# GD32E502 register map
File version: 1.0
CPU: CM33 r0p4, little endian, MPU, FPU, 4 interrupt priority bits
Registers are 32-bit, read-write, reset 0x0 unless marked. A register's access mark holds for its fields unless they carry their own. Offsets are from the block's base; [hi:lo] are bit positions; {n}, {i} and the like mark numbered series.

## TIMER0 — Advanced-timers
Base 0x40012C00
Same registers: TIMER7 0x40013400, TIMER19 0x40015000, TIMER20 0x40015400
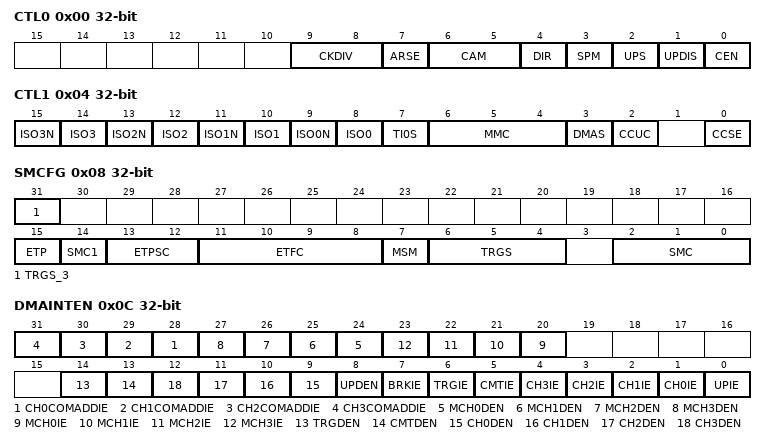
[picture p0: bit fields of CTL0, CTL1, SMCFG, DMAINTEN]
0x00 CTL0 — control register 0
  [9:8] CKDIV — Clock division
  [7] ARSE — Auto-reload shadow enable
  [6:5] CAM — Counter aligns mode selection
  [4] DIR — Direction
  [3] SPM — Single pulse mode
  [2] UPS — Update source
  [1] UPDIS — Update disable
  [0] CEN — Counter enable
0x04 CTL1 — control register 1
  [2n+9] ISO{n}N (n=0..3) — Idle state of channel {n} complementary output
  [2n+8] ISO{n} (n=0..3) — Idle state of channel {n} output
  [7] TI0S — Channel 0 trigger input selection
  [6:4] MMC — Master mode control
  [3] DMAS — DMA request source selection
  [2] CCUC — Commutation control shadow register update control
  [0] CCSE — Commutation control shadow enable
0x08 SMCFG — slave mode configuration register
  [31] TRGS_3 — 3th bit of TRGS
  [15] ETP — External trigger polarity
  [14] SMC1 — Part of SMC for enable External clock mode1
  [13:12] ETPSC — External trigger prescaler
  [11:8] ETFC — External trigger filter control
  [7] MSM — Master/Slave mode
  [6:4] TRGS — Trigger selection
  [2:0] SMC — Slave mode selection
0x0C DMAINTEN — DMA/Interrupt enable register
  [n+28] CH{n}COMADDIE (n=0..3) — Channel {n} additional compare interrupt enable
  [n+24] MCH{n}DEN (n=0..3) — Multi mode channel {n} capture/compare DMA request enable
  [n+20] MCH{n}IE (n=0..3) — Multi mode channel {n} capture/compare interrupt enable
  [14] TRGDEN — Trigger DMA request enable
  [13] CMTDEN — Commutation DMA request enable
  [n+9] CH{n}DEN (n=0..3) — Channel {n} capture/compare DMA request enable
  [8] UPDEN — Update DMA request enable
  [7] BRKIE — Break interrupt enable
  [6] TRGIE — Trigger interrupt enable
  [5] CMTIE — commutation interrupt enable
  [n+1] CH{n}IE (n=0..3) — Channel {n} capture/compare interrupt enable
  [0] UPIE — Update interrupt enable
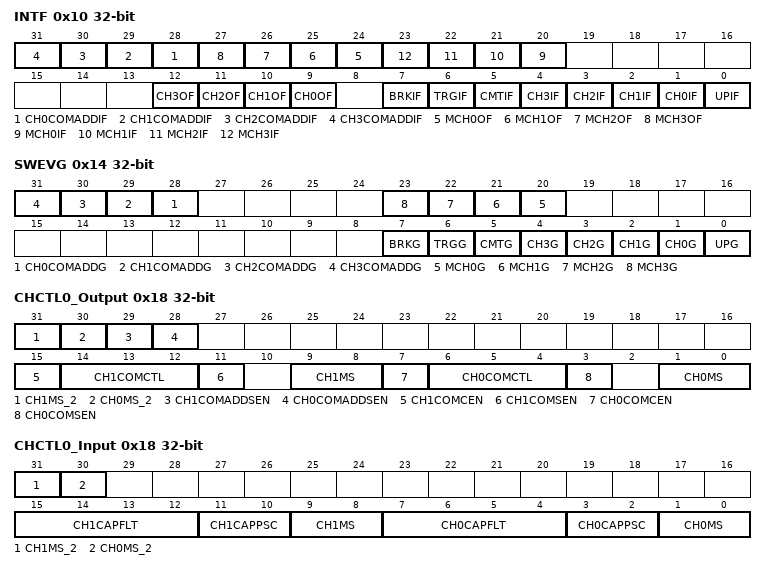
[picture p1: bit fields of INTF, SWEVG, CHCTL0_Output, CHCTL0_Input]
0x10 INTF — Interrupt flag register
  [n+28] CH{n}COMADDIF (n=0..3) — Channel {n} additional compare interrupt flag
  [n+24] MCH{n}OF (n=0..3) — Multi mode channel {n} over capture flag
  [n+20] MCH{n}IF (n=0..3) — Multi mode channel {n} capture/compare interrupt flag
  [n+9] CH{n}OF (n=0..3) — Channel {n} over capture flag
  [7] BRKIF — Break interrupt flag
  [6] TRGIF — Trigger interrupt flag
  [5] CMTIF — Channel commutation interrupt flag
  [n+1] CH{n}IF (n=0..3) — Channel {n} capture/compare interrupt flag
  [0] UPIF — Update interrupt flag
0x14 SWEVG wo — Software event generation register
  [n+28] CH{n}COMADDG (n=0..3) — Channel {n} additional compare event generation
  [n+20] MCH{n}G (n=0..3) — Multi mode channel {n} capture or compare event generation
  [7] BRKG — Break event generation
  [6] TRGG — Trigger event generation
  [5] CMTG — Channel commutation event generation
  [n+1] CH{n}G (n=0..3) — Channel {n} capture or compare event generation
  [0] UPG — Update event generation
0x18 CHCTL0_Output — Channel control register 0 (output mode)
  [31] CH1MS_2 — 2th bit of CH1MS
  [30] CH0MS_2 — 2th bit of CH0MS
  [29] CH1COMADDSEN — Channel 1 additional compare output shadow enable
  [28] CH0COMADDSEN — Channel 0 additional compare output shadow enable
  [15] CH1COMCEN — Channel 1 output compare clear enable
  [14:12] CH1COMCTL — Channel 1 compare output control
  [11] CH1COMSEN — Channel 1 output compare shadow enable
  [9:8] CH1MS — Channel 1 mode selection
  [7] CH0COMCEN — Channel 0 output compare clear enable
  [6:4] CH0COMCTL — Channel 0 compare output control
  [3] CH0COMSEN — Channel 0 compare output shadow enable
  [1:0] CH0MS — Channel 0 I/O mode selection
0x18 CHCTL0_Input (alternate view of CHCTL0_Output) — Channel control register 0 (input mode)
  [31] CH1MS_2 — 2th bit of CH1MS
  [30] CH0MS_2 — 2th bit of CH0MS
  [15:12] CH1CAPFLT — Channel 1 input capture filter control
  [11:10] CH1CAPPSC — Channel 1 input capture prescaler
  [9:8] CH1MS — Channel 1 mode selection
  [7:4] CH0CAPFLT — Channel 0 input capture filter control
  [3:2] CH0CAPPSC — Channel 0 input capture prescaler
  [1:0] CH0MS — Channel 0 mode selection
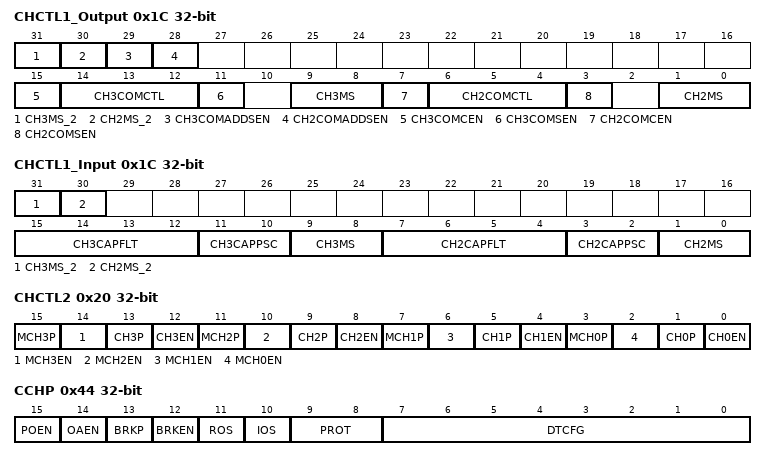
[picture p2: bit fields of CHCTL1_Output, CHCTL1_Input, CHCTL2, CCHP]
0x1C CHCTL1_Output — Channel control register 1 (output mode)
  [31] CH3MS_2 — 2th bit of CH3MS
  [30] CH2MS_2 — 2th bit of CH2MS
  [29] CH3COMADDSEN — Channel 3 additional compare output shadow enable
  [28] CH2COMADDSEN — Channel 2 additional compare output shadow enable
  [15] CH3COMCEN — Channel 3 output compare clear enable
  [14:12] CH3COMCTL — Channel 3 compare output control
  [11] CH3COMSEN — Channel 3 output compare shadow enable
  [9:8] CH3MS — Channel 3 mode selection
  [7] CH2COMCEN — Channel 2 output compare clear enable
  [6:4] CH2COMCTL — Channel 2 compare output control
  [3] CH2COMSEN — Channel 2 compare output shadow enable
  [1:0] CH2MS — Channel 2 I/O mode selection
0x1C CHCTL1_Input (alternate view of CHCTL1_Output) — Channel control register 1 (input mode)
  [31] CH3MS_2 — 2th bit of CH3MS
  [30] CH2MS_2 — 2th bit of CH2MS
  [15:12] CH3CAPFLT — Channel 3 input capture filter control
  [11:10] CH3CAPPSC — Channel 3 input capture prescaler
  [9:8] CH3MS — Channel 3 mode selection
  [7:4] CH2CAPFLT — Channel 2 input capture filter control
  [3:2] CH2CAPPSC — Channel 2 input capture prescaler
  [1:0] CH2MS — Channel 2 mode selection
0x20 CHCTL2 — Channel control register 2
  [15] MCH3P — Multi mode channel 3 capture/compare polarity
  [14] MCH3EN — Multi mode channel 3 capture/compare enable
  [4n+1] CH{n}P (n=0..3) — Channel {n} capture/compare function polarity
  [4n] CH{n}EN (n=0..3) — Channel {n} capture/compare function enable
  [11] MCH2P — Multi mode channel 2 capture/compare polarity
  [10] MCH2EN — Multi mode channel 2 output enable
  [7] MCH1P — Multi mode channel 1 output polarity
  [6] MCH1EN — Multi mode channel 1 output enable
  [3] MCH0P — Multi mode channel 0 output polarity
  [2] MCH0EN — Multi mode channel 0 capture/compare enable
0x24 CNT — counter
  [15:0] CNT — current counter value
0x28 PSC — prescaler
  [15:0] PSC — Prescaler value of the counter clock
0x2C CAR — Counter auto reload register
  [15:0] CARL — Counter auto reload value
0x30 CREP — Counter repetition register
  [7:0] CREP — Counter repetition value
0x34 CH0CV — Channel 0 capture/compare value register
  [15:0] CH0VAL — Capture or compare value of channel0
0x38 CH1CV — Channel 1 capture/compare value register
  [15:0] CH1VAL — Capture or compare value of channel1
0x3C CH2CV — Channel 2 capture/compare value register
  [15:0] CH2VAL — Capture or compare value of channel 2
0x40 CH3CV — Channel 3 capture/compare value register
  [15:0] CH3VAL — Capture or compare value of channel 3
0x44 CCHP — channel complementary protection register
  [15] POEN — Primary output enable
  [14] OAEN — Output automatic enable
  [13] BRKP — Break polarity
  [12] BRKEN — Break enable
  [11] ROS — Run mode off-state configure
  [10] IOS — Idle mode off-state configure
  [9:8] PROT — Complementary register protect control
  [7:0] DTCFG — Dead time configure
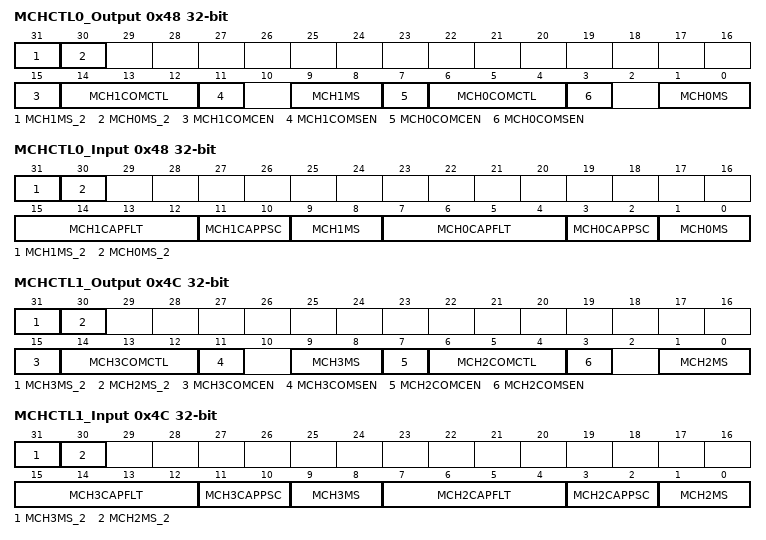
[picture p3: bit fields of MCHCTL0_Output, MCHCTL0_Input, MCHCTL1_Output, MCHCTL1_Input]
0x48 MCHCTL0_Output — Multi mode channel control register 0 (output mode)
  [31] MCH1MS_2 — Multi mode channel 1 I/O mode selection
  [30] MCH0MS_2 — Multi mode channel 0 I/O mode selection
  [15] MCH1COMCEN — Multi mode channel 1 output compare clear enable
  [14:12] MCH1COMCTL — Multi mode channel 1 compare output control
  [11] MCH1COMSEN — Multi mode channel 1 output compare shadow enable
  [9:8] MCH1MS — Multi mode channel 1 I/O mode selection
  [7] MCH0COMCEN — Multi mode channel 0 output compare clear enable
  [6:4] MCH0COMCTL — Multi mode channel 0 output compare control
  [3] MCH0COMSEN — Multi mode channel 0 output compare shadow enable
  [1:0] MCH0MS — Multi mode channel 0 I/O mode selection
0x48 MCHCTL0_Input (alternate view of MCHCTL0_Output) — Multi mode channel control register 0 (input mode)
  [31] MCH1MS_2 — Multi mode channel 1 I/O mode selection
  [30] MCH0MS_2 — Multi mode channel 0 I/O mode selection
  [15:12] MCH1CAPFLT — Multi mode channel 1 input capture filter control
  [11:10] MCH1CAPPSC — Multi mode channel 1 input capture prescaler
  [9:8] MCH1MS — Multi mode channel 1 I/O mode selection
  [7:4] MCH0CAPFLT — Multi mode channel 0 input capture filter control
  [3:2] MCH0CAPPSC — Multi mode channel 0 input capture prescaler
  [1:0] MCH0MS — Multi mode channel 0 I/O mode selection
0x4C MCHCTL1_Output — Multi mode channel control register 1 (output mode)
  [31] MCH3MS_2 — 2th bit of MCH3MS
  [30] MCH2MS_2 — 2th bit of MCH2MS
  [15] MCH3COMCEN — Multi mode channel 3 output compare clear enable
  [14:12] MCH3COMCTL — Multi mode channel 3 compare output control
  [11] MCH3COMSEN — Multi mode channel 3 output compare shadow enable
  [9:8] MCH3MS — Multi mode channel 3 I/O mode selection
  [7] MCH2COMCEN — Multi mode channel 2 output compare clear enable
  [6:4] MCH2COMCTL — Multi mode channel 2 compare output control
  [3] MCH2COMSEN — Multi mode channel 2 output compare shadow enable
  [1:0] MCH2MS — Multi mode channel 2 I/O mode selection
0x4C MCHCTL1_Input (alternate view of MCHCTL1_Output) — Multi mode channel control register 1(input mode)
  [31] MCH3MS_2 — 2th bit of MCH3MS
  [30] MCH2MS_2 — 2th bit of MCH2MS
  [15:12] MCH3CAPFLT — Multi mode channel 3 input capture filter control
  [11:10] MCH3CAPPSC — Multi mode channel 3 input capture prescaler
  [9:8] MCH3MS — Multi mode channel 3 I/O mode selection.
  [7:4] MCH2CAPFLT — Multi mode channel 2 input capture filter control
  [3:2] MCH2CAPPSC — Multi mode channel 2 input capture prescaler
  [1:0] MCH2MS — Multi mode channel 2 I/O mode selection
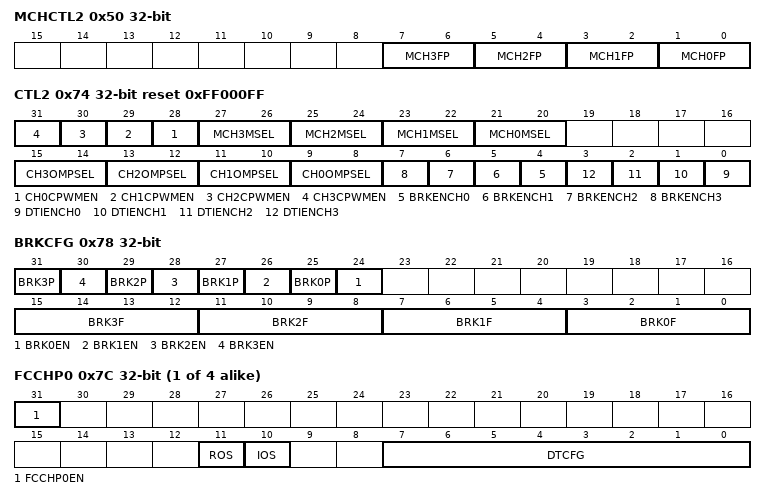
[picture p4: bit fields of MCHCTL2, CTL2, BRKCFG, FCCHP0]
0x50 MCHCTL2 — Multi mode channel control register 2
  [2n+1:2n] MCH{n}FP (n=0..3) — Multi mode channel {n} capture/compare free polarity
{0x54+4i} MCH{i}CV (i=0..2) — Multi mode channel {i} capture/compare value register
  [15:0] MCH{i}VAL — Capture/compare value of multi mode channel {i}
0x60 MCH3VAL — Capture/compare value of multi mode channel 3
  [15:0] MCH3VAL — Capture/compare value of channel 3
{0x64+4i} CH{i}COMV_ADD (i=0..3) — Channel {i} additional compare value register
  [15:0] CH{i}COMVAL_ADD — Additional compare value of channel {i}
0x74 CTL2 reset 0xFF000FF — Control register 2
  [n+28] CH{n}CPWMEN (n=0..3) — Channel {n} composite PWM mode enable
  [2n+21:2n+20] MCH{n}MSEL (n=0..3) — Multi mode channel {n} mode select
  [2n+9:2n+8] CH{n}OMPSEL (n=0..3) — Channel {n} output match pulse select
  [n+4] BRKENCH{n} (n=0..3) — Break control enable for channel {n}
  [n] DTIENCH{n} (n=0..3) — Dead time inserted enable for channel {n}
0x78 BRKCFG — Break configuration register
  [2n+25] BRK{n}P (n=0..3) — BRKIN{n} input signal polarity
  [2n+24] BRK{n}EN (n=0..3) — BRKIN{n} input signal enable
  [4n+3:4n] BRK{n}F (n=0..3) — BRKIN{n} input signal filter
{0x7C+4i} FCCHP{i} (i=0..3) — Free complementary channel protection register {i}
  [31] FCCHP{i}EN — Free complementary channel protection register {i} enable
  [11] ROS — Run mode off-state configure
  [10] IOS — Idle mode off-state configure
  [7:0] DTCFG — Dead time configure
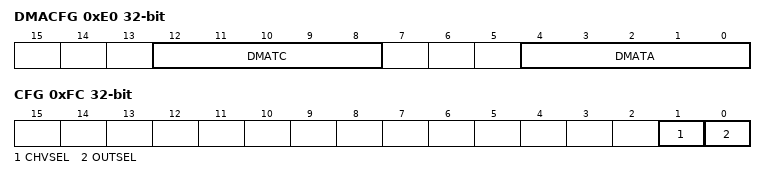
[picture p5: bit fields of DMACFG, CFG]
0xE0 DMACFG — DMA configuration register
  [12:8] DMATC — DMA transfer count
  [4:0] DMATA — DMA transfer access start address
0xE4 DMATB — DMA transfer buffer register
  [15:0] DMATB — DMA transfer buffer
0xFC CFG — Configuration register
  [1] CHVSEL — Write CHxVAL register selection
  [0] OUTSEL — The output value selection
